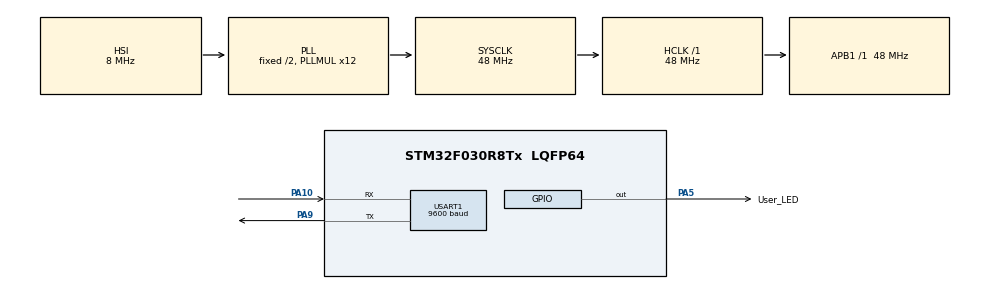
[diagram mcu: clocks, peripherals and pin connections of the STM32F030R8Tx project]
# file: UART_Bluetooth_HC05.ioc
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Mcu.Family=STM32F0
Mcu.Name=STM32F030R8Tx
Mcu.Package=LQFP64
PA10.Mode=Asynchronous
PA10.Signal=USART1_RX
PA13.Mode=Serial_Wire
PA13.Signal=SYS_SWDIO
PA14.Mode=Serial_Wire
PA14.Signal=SYS_SWCLK
PA5.GPIO_Label=User_LED
PA5.GPIO_Speed=GPIO_SPEED_FREQ_MEDIUM
PA5.Signal=GPIO_Output
PA9.Mode=Asynchronous
PA9.Signal=USART1_TX
ProjectManager.HeapSize=0x200
ProjectManager.StackSize=0x400
ProjectManager.TargetToolchain=STM32CubeIDE
RCC.AHBFreq_Value=48000000
RCC.APB1Freq_Value=48000000
RCC.APB1TimFreq_Value=48000000
RCC.HCLKFreq_Value=48000000
RCC.PLLMUL=RCC_PLL_MUL12
RCC.SYSCLKFreq_VALUE=48000000
RCC.SYSCLKSource=RCC_SYSCLKSOURCE_PLLCLK
USART1.BaudRate=9600
USART1.VirtualMode-Asynchronous=VM_ASYNC
board=NUCLEO-F030R8

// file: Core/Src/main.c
/* USER CODE BEGIN Header */
/**
  ******************************************************************************
  * @file           : main.c
  * @brief          : Main program body
  ******************************************************************************
  * @attention
  *
  * Copyright (c) 2026 STMicroelectronics.
  * All rights reserved.
  *
  * This software is licensed under terms that can be found in the LICENSE file
  * in the root directory of this software component.
  * If no LICENSE file comes with this software, it is provided AS-IS.
  *
  ******************************************************************************
  */
/* USER CODE END Header */
#include "main.h"

/* USER CODE BEGIN Includes */
#include "string.h"
/* USER CODE END Includes */

UART_HandleTypeDef huart1;

/* USER CODE BEGIN PV */
uint8_t message[10];     //gonderilecek veya alinacak karakterleri kayit etmek icin
/* USER CODE END PV */

void SystemClock_Config(void);
static void MX_GPIO_Init(void);
static void MX_USART1_UART_Init(void);

int main(void)
{

  /* MCU Configuration--------------------------------------------------------*/

  /* Reset of all peripherals, Initializes the Flash interface and the Systick. */
  HAL_Init();

  /* Configure the system clock */
  SystemClock_Config();

  /* Initialize all configured peripherals */
  MX_GPIO_Init();
  MX_USART1_UART_Init();

  /* Infinite loop */
  while (1)
  {

    /* USER CODE BEGIN 3 */
	  HAL_UART_Receive(&huart1, message, 10, 1000);   //bluetooth modulunden message dizisine veri almak icin yazildi
	  //HAL_UART_Transmit(&huart1, (uint8_t*)"Huseyinn\r\n", 12, 1000);   //huseyinn yazisini bluetooth uzerinden göndermek icin yazildi
	  //HAL_Delay(500);
	  HAL_UART_Transmit(&huart1, message, 10, 1000);   //message dizisindeki karakterleri bluetooth uzerinden gondermek icin yazildi
  }
  /* USER CODE END 3 */
}

void SystemClock_Config(void)
{
  RCC_OscInitTypeDef RCC_OscInitStruct = {0};
  RCC_ClkInitTypeDef RCC_ClkInitStruct = {0};
  RCC_PeriphCLKInitTypeDef PeriphClkInit = {0};

  /** Initializes the RCC Oscillators according to the specified parameters
  * in the RCC_OscInitTypeDef structure.
  */
  RCC_OscInitStruct.OscillatorType = RCC_OSCILLATORTYPE_HSI;
  RCC_OscInitStruct.HSIState = RCC_HSI_ON;
  RCC_OscInitStruct.HSICalibrationValue = RCC_HSICALIBRATION_DEFAULT;
  RCC_OscInitStruct.PLL.PLLState = RCC_PLL_ON;
  RCC_OscInitStruct.PLL.PLLSource = RCC_PLLSOURCE_HSI;
  RCC_OscInitStruct.PLL.PLLMUL = RCC_PLL_MUL12;
  RCC_OscInitStruct.PLL.PREDIV = RCC_PREDIV_DIV1;
  if (HAL_RCC_OscConfig(&RCC_OscInitStruct) != HAL_OK)
  {
    Error_Handler();
  }

  /** Initializes the CPU, AHB and APB buses clocks
  */
  RCC_ClkInitStruct.ClockType = RCC_CLOCKTYPE_HCLK|RCC_CLOCKTYPE_SYSCLK
                              |RCC_CLOCKTYPE_PCLK1;
  RCC_ClkInitStruct.SYSCLKSource = RCC_SYSCLKSOURCE_PLLCLK;
  RCC_ClkInitStruct.AHBCLKDivider = RCC_SYSCLK_DIV1;
  RCC_ClkInitStruct.APB1CLKDivider = RCC_HCLK_DIV1;

  if (HAL_RCC_ClockConfig(&RCC_ClkInitStruct, FLASH_LATENCY_1) != HAL_OK)
  {
    Error_Handler();
  }
  PeriphClkInit.PeriphClockSelection = RCC_PERIPHCLK_USART1;
  PeriphClkInit.Usart1ClockSelection = RCC_USART1CLKSOURCE_PCLK1;
  if (HAL_RCCEx_PeriphCLKConfig(&PeriphClkInit) != HAL_OK)
  {
    Error_Handler();
  }
}

static void MX_USART1_UART_Init(void)
{

  huart1.Instance = USART1;
  huart1.Init.BaudRate = 9600;
  huart1.Init.WordLength = UART_WORDLENGTH_8B;
  huart1.Init.StopBits = UART_STOPBITS_1;
  huart1.Init.Parity = UART_PARITY_NONE;
  huart1.Init.Mode = UART_MODE_TX_RX;
  huart1.Init.HwFlowCtl = UART_HWCONTROL_NONE;
  huart1.Init.OverSampling = UART_OVERSAMPLING_16;
  huart1.Init.OneBitSampling = UART_ONE_BIT_SAMPLE_DISABLE;
  huart1.AdvancedInit.AdvFeatureInit = UART_ADVFEATURE_NO_INIT;
  if (HAL_UART_Init(&huart1) != HAL_OK)
  {
    Error_Handler();
  }

}

static void MX_GPIO_Init(void)
{
  GPIO_InitTypeDef GPIO_InitStruct = {0};

  /* GPIO Ports Clock Enable */
  __HAL_RCC_GPIOA_CLK_ENABLE();

  /*Configure GPIO pin Output Level */
  HAL_GPIO_WritePin(User_LED_GPIO_Port, User_LED_Pin, GPIO_PIN_RESET);

  /*Configure GPIO pin : User_LED_Pin */
  GPIO_InitStruct.Pin = User_LED_Pin;
  GPIO_InitStruct.Mode = GPIO_MODE_OUTPUT_PP;
  GPIO_InitStruct.Pull = GPIO_NOPULL;
  GPIO_InitStruct.Speed = GPIO_SPEED_FREQ_MEDIUM;
  HAL_GPIO_Init(User_LED_GPIO_Port, &GPIO_InitStruct);

}

void Error_Handler(void)
{
  __disable_irq();
  while (1)
  {
  }
}
